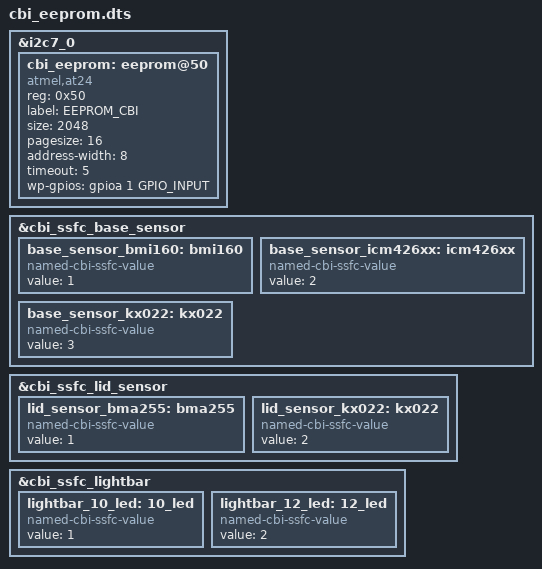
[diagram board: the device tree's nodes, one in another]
/* Copyright 2021 The Chromium OS Authors. All rights reserved.
 * Use of this source code is governed by a BSD-style license that can be
 * found in the LICENSE file.
 */

&i2c7_0 {
	cbi_eeprom: eeprom@50 {
		compatible = "atmel,at24";
		reg = <0x50>;
		label = "EEPROM_CBI";
		size = <2048>;
		pagesize = <16>;
		address-width = <8>;
		timeout = <5>;
		/* gpio_ec_wp_l */
		wp-gpios = <&gpioa 1 GPIO_INPUT>;
	};
};

&cbi_ssfc_base_sensor {
	base_sensor_bmi160: bmi160 {
		compatible = "named-cbi-ssfc-value";
		status = "okay";

		value = <1>;
	};
	base_sensor_icm426xx: icm426xx {
		compatible = "named-cbi-ssfc-value";
		status = "okay";

		value = <2>;
	};
	base_sensor_kx022: kx022 {
		compatible = "named-cbi-ssfc-value";
		status = "okay";

		value = <3>;
	};
};

&cbi_ssfc_lid_sensor {
	lid_sensor_bma255: bma255 {
		compatible = "named-cbi-ssfc-value";
		status = "okay";

		value = <1>;
	};
	lid_sensor_kx022: kx022 {
		compatible = "named-cbi-ssfc-value";
		status = "okay";

		value = <2>;
	};
};

&cbi_ssfc_lightbar {
	lightbar_10_led: 10_led {
		compatible = "named-cbi-ssfc-value";
		status = "okay";

		value = <1>;
	};
	lightbar_12_led: 12_led {
		compatible = "named-cbi-ssfc-value";
		status = "okay";

		value = <2>;
	};
};
